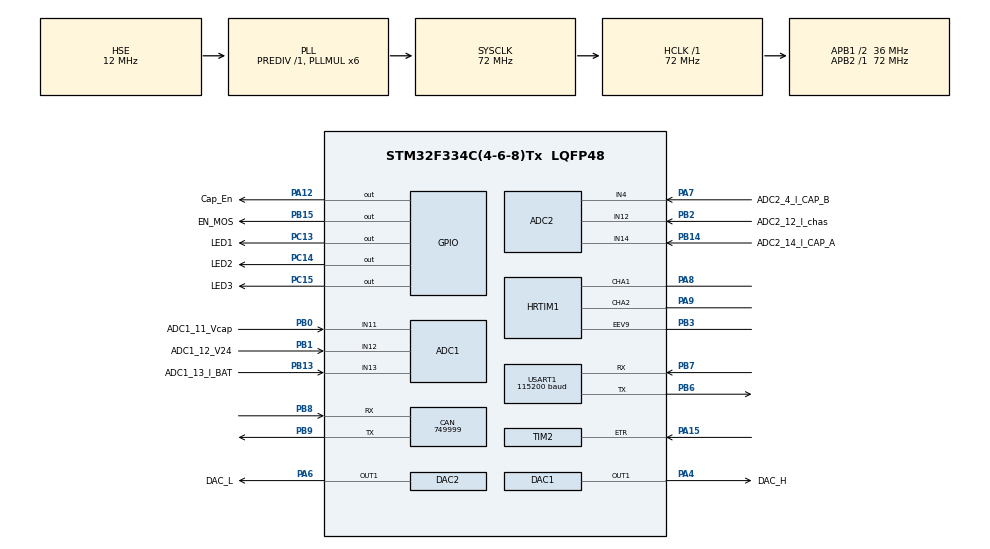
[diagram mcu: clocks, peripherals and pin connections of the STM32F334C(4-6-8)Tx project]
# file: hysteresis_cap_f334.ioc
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ADC1.Channel-1\#ChannelRegularConversion=ADC_CHANNEL_13
ADC1.Channel-2\#ChannelRegularConversion=ADC_CHANNEL_11
ADC1.Channel-3\#ChannelRegularConversion=ADC_CHANNEL_12
ADC1.ContinuousConvMode=ENABLE
ADC1.DMAContinuousRequests=ENABLE
ADC1.NbrOfConversion=3
ADC1.NbrOfConversionFlag=1
ADC1.Offset-1\#ChannelRegularConversion=0
ADC1.Offset-2\#ChannelRegularConversion=0
ADC1.Offset-3\#ChannelRegularConversion=0
ADC1.OffsetNumber-1\#ChannelRegularConversion=ADC_OFFSET_NONE
ADC1.OffsetNumber-2\#ChannelRegularConversion=ADC_OFFSET_NONE
ADC1.OffsetNumber-3\#ChannelRegularConversion=ADC_OFFSET_NONE
ADC1.Rank-1\#ChannelRegularConversion=1
ADC1.Rank-2\#ChannelRegularConversion=2
ADC1.Rank-3\#ChannelRegularConversion=3
ADC1.SamplingTime-1\#ChannelRegularConversion=ADC_SAMPLETIME_19CYCLES_5
ADC1.SamplingTime-2\#ChannelRegularConversion=ADC_SAMPLETIME_19CYCLES_5
ADC1.SamplingTime-3\#ChannelRegularConversion=ADC_SAMPLETIME_19CYCLES_5
ADC1.SubFamily=STM32F334x8
ADC1.master=1
ADC2.Channel-1\#ChannelRegularConversion=ADC_CHANNEL_14
ADC2.Channel-2\#ChannelRegularConversion=ADC_CHANNEL_12
ADC2.Channel-3\#ChannelRegularConversion=ADC_CHANNEL_4
ADC2.ContinuousConvMode=ENABLE
ADC2.DMAContinuousRequests=ENABLE
ADC2.NbrOfConversion=3
ADC2.NbrOfConversionFlag=1
ADC2.Offset-1\#ChannelRegularConversion=0
ADC2.Offset-2\#ChannelRegularConversion=0
ADC2.Offset-3\#ChannelRegularConversion=0
ADC2.OffsetNumber-1\#ChannelRegularConversion=ADC_OFFSET_NONE
ADC2.OffsetNumber-2\#ChannelRegularConversion=ADC_OFFSET_NONE
ADC2.OffsetNumber-3\#ChannelRegularConversion=ADC_OFFSET_NONE
ADC2.Rank-1\#ChannelRegularConversion=1
ADC2.Rank-2\#ChannelRegularConversion=2
ADC2.Rank-3\#ChannelRegularConversion=3
ADC2.SamplingTime-1\#ChannelRegularConversion=ADC_SAMPLETIME_19CYCLES_5
ADC2.SamplingTime-2\#ChannelRegularConversion=ADC_SAMPLETIME_19CYCLES_5
ADC2.SamplingTime-3\#ChannelRegularConversion=ADC_SAMPLETIME_19CYCLES_5
ADC2.SequencerNbRanks=1
CAN.CalculateBaudRate=749999
CAN.CalculateTimeBit=1333
CAN.CalculateTimeQuantum=444.44444444444446
DAC1.DAC_Trigger=DAC_TRIGGER_T15_TRGO
DAC2.DAC_Trigger=DAC_TRIGGER_T15_TRGO
Dma.ADC1.2.Direction=DMA_PERIPH_TO_MEMORY
Dma.ADC1.2.Instance=DMA1_Channel1
Dma.ADC1.2.MemDataAlignment=DMA_MDATAALIGN_HALFWORD
Dma.ADC1.2.MemInc=DMA_MINC_ENABLE
Dma.ADC1.2.Mode=DMA_CIRCULAR
Dma.ADC1.2.PeriphDataAlignment=DMA_PDATAALIGN_HALFWORD
Dma.ADC1.2.PeriphInc=DMA_PINC_DISABLE
Dma.ADC1.2.Priority=DMA_PRIORITY_LOW
Dma.ADC2.3.Direction=DMA_PERIPH_TO_MEMORY
Dma.ADC2.3.Instance=DMA1_Channel2
Dma.ADC2.3.MemDataAlignment=DMA_MDATAALIGN_HALFWORD
Dma.ADC2.3.MemInc=DMA_MINC_ENABLE
Dma.ADC2.3.Mode=DMA_CIRCULAR
Dma.ADC2.3.PeriphDataAlignment=DMA_PDATAALIGN_HALFWORD
Dma.ADC2.3.PeriphInc=DMA_PINC_DISABLE
Dma.ADC2.3.Priority=DMA_PRIORITY_LOW
Dma.Request0=USART1_RX
Dma.Request1=USART1_TX
Dma.Request2=ADC1
Dma.Request3=ADC2
Dma.USART1_RX.0.Direction=DMA_PERIPH_TO_MEMORY
Dma.USART1_RX.0.Instance=DMA1_Channel5
Dma.USART1_RX.0.MemDataAlignment=DMA_MDATAALIGN_BYTE
Dma.USART1_RX.0.MemInc=DMA_MINC_ENABLE
Dma.USART1_RX.0.Mode=DMA_CIRCULAR
Dma.USART1_RX.0.PeriphDataAlignment=DMA_PDATAALIGN_BYTE
Dma.USART1_RX.0.PeriphInc=DMA_PINC_DISABLE
Dma.USART1_RX.0.Priority=DMA_PRIORITY_LOW
Dma.USART1_TX.1.Direction=DMA_MEMORY_TO_PERIPH
Dma.USART1_TX.1.Instance=DMA1_Channel4
Dma.USART1_TX.1.MemDataAlignment=DMA_MDATAALIGN_BYTE
Dma.USART1_TX.1.MemInc=DMA_MINC_ENABLE
Dma.USART1_TX.1.Mode=DMA_NORMAL
Dma.USART1_TX.1.PeriphDataAlignment=DMA_PDATAALIGN_BYTE
Dma.USART1_TX.1.PeriphInc=DMA_PINC_DISABLE
Dma.USART1_TX.1.Priority=DMA_PRIORITY_LOW
HRTIM1.CalibrationRate_nonIT=HRTIM_CALIBRATIONRATE_14
HRTIM1.CompareUnit1-Output_TA1TA2=HRTIM_COMPAREUNIT_1
HRTIM1.CompareUnit2-Output_TA1TA2=HRTIM_COMPAREUNIT_2
HRTIM1.CompareUnit3-Output_TA1TA2=HRTIM_COMPAREUNIT_3
HRTIM1.CompareValue1-Output_TA1TA2=1600
HRTIM1.CompareValue2-Output_TA1TA2=65043
HRTIM1.CompareValue3-Output_TA1TA2=1500
HRTIM1.Enable=HRTIM_BURSTMODECTL_DISABLED
HRTIM1.EnableCalibration=DLLSimpleCalibration
HRTIM1.NumberInterruptRequests-Output_TA1TA2=0
HRTIM1.NumberResetSource1-Output_TA1TA2=2
HRTIM1.NumberResetSource2_TA=1
HRTIM1.NumberResetTrigger-Output_TA1TA2=1
HRTIM1.NumberSetSource1-Output_TA1TA2=1
HRTIM1.NumberSetSource2_TA=1
HRTIM1.NumberUpdateTrigger-Output_TA1TA2=0
HRTIM1.Periode_TA=65503
HRTIM1.Polarity_EEV9=HRTIM_EVENTPOLARITY_HIGH
HRTIM1.PreloadEnable-Output_TA1TA2=HRTIM_PRELOAD_DISABLED
HRTIM1.PrescalerRatio_TA=HRTIM_PRESCALERRATIO_MUL32
HRTIM1.RepetitionUpdate-Output_TA1TA2=HRTIM_UPDATEONREPETITION_DISABLED
HRTIM1.ResetOutput1_Source1-Output_TA1TA2=HRTIM_OUTPUTRESET_NONE
HRTIM1.ResetOutput1_Source2-Output_TA1TA2=HRTIM_OUTPUTRESET_TIMPER
HRTIM1.ResetOutput2_Source1-Output_TA1TA2=HRTIM_OUTPUTRESET_TIMCMP3
HRTIM1.ResetTrigger1-Output_TA1TA2=HRTIM_TIMRESETTRIGGER_EEV_9
HRTIM1.Sensitivity_EEV9=HRTIM_EVENTSENSITIVITY_FALLINGEDGE
HRTIM1.SetOutput1_Source1-Output_TA1TA2=HRTIM_OUTPUTSET_TIMCMP1
HRTIM1.SetOutput2_Source1-Output_TA1TA2=HRTIM_OUTPUTSET_TIMCMP2
HRTIM1.SyncOptions=HRTIM_SYNCOPTION_NONE
Mcu.Family=STM32F3
Mcu.Name=STM32F334C(4-6-8)Tx
Mcu.Package=LQFP48
NVIC.DMA1_Channel4_IRQn=true\:0\:0\:false\:false\:true\:true\:true\:true
NVIC.DMA1_Channel5_IRQn=true\:0\:0\:false\:false\:true\:true\:true\:true
NVIC.PriorityGroup=NVIC_PRIORITYGROUP_4
NVIC.TIM1_BRK_TIM15_IRQn=true\:0\:0\:false\:false\:false\:true\:false\:true
NVIC.USART1_IRQn=true\:0\:0\:false\:false\:true\:true\:true\:true
PA12.GPIO_Label=Cap_En
PA12.Signal=GPIO_Output
PA13.Mode=Serial_Wire
PA13.Signal=SYS_JTMS-SWDIO
PA14.Mode=Serial_Wire
PA14.Signal=SYS_JTCK-SWCLK
PA15.Signal=S_TIM2_CH1_ETR
PA4.GPIO_Label=DAC_H
PA4.Signal=COMP_DAC11_group
PA6.GPIO_Label=DAC_L
PA6.Signal=COMP_DAC21_group
PA7.GPIO_Label=ADC2_4_I_CAP_B
PA7.Mode=IN4-Single-Ended
PA7.Signal=ADC2_IN4
PA8.Mode=Output_TA1TA2
PA8.Signal=HRTIM1_CHA1
PA9.Mode=Output_TA1TA2
PA9.Signal=HRTIM1_CHA2
PB0.GPIO_Label=ADC1_11_Vcap
PB0.Mode=IN11-Single-Ended
PB0.Signal=ADC1_IN11
PB1.GPIO_Label=ADC1_12_V24
PB1.Mode=IN12-Single-Ended
PB1.Signal=ADC1_IN12
PB13.GPIO_Label=ADC1_13_I_BAT
PB13.Mode=IN13-Single-Ended
PB13.Signal=ADC1_IN13
PB14.GPIO_Label=ADC2_14_I_CAP_A
PB14.Mode=IN14-Single-Ended
PB14.Signal=ADC2_IN14
PB15.GPIO_Label=EN_MOS
PB15.Signal=GPIO_Output
PB2.GPIO_Label=ADC2_12_I_chas
PB2.Mode=IN12-Single-Ended
PB2.Signal=ADC2_IN12
PB3.Mode=External_Evt_enable9
PB3.Signal=HRTIM1_EEV9
PB6.Mode=Asynchronous
PB6.Signal=USART1_TX
PB7.Mode=Asynchronous
PB7.Signal=USART1_RX
PB8.Mode=CAN_Activate
PB8.Signal=CAN_RX
PB9.Mode=CAN_Activate
PB9.Signal=CAN_TX
PC13.GPIO_Label=LED1
PC13.Signal=GPIO_Output
PC14\ /\ OSC32_IN.GPIO_Label=LED2
PC14\ /\ OSC32_IN.Signal=GPIO_Output
PC15\ /\ OSC32_OUT.GPIO_Label=LED3
PC15\ /\ OSC32_OUT.Signal=GPIO_Output
PF0\ /\ OSC_IN.Mode=HSE-External-Oscillator
PF0\ /\ OSC_IN.Signal=RCC_OSC_IN
PF1\ /\ OSC_OUT.Mode=HSE-External-Oscillator
PF1\ /\ OSC_OUT.Signal=RCC_OSC_OUT
ProjectManager.HeapSize=0x200
ProjectManager.StackSize=0x400
ProjectManager.TargetToolchain=MDK-ARM V5.32
RCC.AHBFreq_Value=72000000
RCC.APB1CLKDivider=RCC_HCLK_DIV2
RCC.APB1Freq_Value=36000000
RCC.APB1TimFreq_Value=72000000
RCC.APB2Freq_Value=72000000
RCC.APB2TimFreq_Value=72000000
RCC.CortexFreq_Value=72000000
RCC.HCLKFreq_Value=72000000
RCC.HRTIMSelection=RCC_HRTIM1CLK_PLLCLK
RCC.HSE_VALUE=12000000
RCC.HSI_VALUE=8000000
RCC.LSE_VALUE=32768
RCC.PLLMUL=RCC_PLL_MUL6
RCC.PLLSourceVirtual=RCC_PLLSOURCE_HSE
RCC.SYSCLKFreq_VALUE=72000000
RCC.SYSCLKSourceVirtual=RCC_SYSCLKSOURCE_PLLCLK
SH.COMP_DAC11_group.0=DAC1_OUT1,DAC_OUT1
SH.COMP_DAC21_group.0=DAC2_OUT1,Switch_Enable_OUT1
SH.S_TIM2_CH1_ETR.0=TIM2_ETR,ClockSourceETR_Mode2
TIM15.AutoReloadPreload=TIM_AUTORELOAD_PRELOAD_ENABLE
TIM15.Period=9
TIM15.Prescaler=71
TIM15.TIM_MasterOutputTrigger=TIM_TRGO_UPDATE
USART1.BaudRate=115200
USART1.OverSampling=UART_OVERSAMPLING_16
USART1.VirtualMode-Asynchronous=VM_ASYNC
VP_TIM15_VS_ClockSourceINT.Mode=Internal
board=custom

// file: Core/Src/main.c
/* USER CODE BEGIN Header */
/**
  ******************************************************************************
  * @file           : main.c
  * @brief          : Main program body
  ******************************************************************************
  * @attention
  *
  * Copyright (c) 2026 STMicroelectronics.
  * All rights reserved.
  *
  * This software is licensed under terms that can be found in the LICENSE file
  * in the root directory of this software component.
  * If no LICENSE file comes with this software, it is provided AS-IS.
  *
  ******************************************************************************
  */
/* USER CODE END Header */
#include "main.h"
#include "adc.h"
#include "can.h"
#include "dac.h"
#include "dma.h"
#include "hrtim.h"
#include "tim.h"
#include "usart.h"
#include "gpio.h"

/* USER CODE BEGIN Includes */
#include "scheduler.h"
/* USER CODE END Includes */

void SystemClock_Config(void);

int main(void)
{

  /* MCU Configuration--------------------------------------------------------*/

  /* Reset of all peripherals, Initializes the Flash interface and the Systick. */
  HAL_Init();

  /* Configure the system clock */
  SystemClock_Config();

  /* Initialize all configured peripherals */
  MX_GPIO_Init();
  MX_DMA_Init();
  MX_CAN_Init();
  MX_DAC1_Init();
  MX_DAC2_Init();
  MX_HRTIM1_Init();
  MX_USART1_UART_Init();
  MX_TIM2_Init();
  MX_ADC1_Init();
  MX_ADC2_Init();
  MX_TIM15_Init();
  /* USER CODE BEGIN 2 */
  Scheduler_ALL_Init_Task();
  /* USER CODE END 2 */

  /* Infinite loop */
  /* USER CODE BEGIN WHILE */
  while (1)
  {
    Scheduler_run();
    /* USER CODE END WHILE */

  }
}

void SystemClock_Config(void)
{
  RCC_OscInitTypeDef RCC_OscInitStruct = {0};
  RCC_ClkInitTypeDef RCC_ClkInitStruct = {0};
  RCC_PeriphCLKInitTypeDef PeriphClkInit = {0};

  /** Initializes the RCC Oscillators according to the specified parameters
  * in the RCC_OscInitTypeDef structure.
  */
  RCC_OscInitStruct.OscillatorType = RCC_OSCILLATORTYPE_HSE;
  RCC_OscInitStruct.HSEState = RCC_HSE_ON;
  RCC_OscInitStruct.HSEPredivValue = RCC_HSE_PREDIV_DIV1;
  RCC_OscInitStruct.HSIState = RCC_HSI_ON;
  RCC_OscInitStruct.PLL.PLLState = RCC_PLL_ON;
  RCC_OscInitStruct.PLL.PLLSource = RCC_PLLSOURCE_HSE;
  RCC_OscInitStruct.PLL.PLLMUL = RCC_PLL_MUL6;
  if (HAL_RCC_OscConfig(&RCC_OscInitStruct) != HAL_OK)
  {
    Error_Handler();
  }

  /** Initializes the CPU, AHB and APB buses clocks
  */
  RCC_ClkInitStruct.ClockType = RCC_CLOCKTYPE_HCLK|RCC_CLOCKTYPE_SYSCLK
                              |RCC_CLOCKTYPE_PCLK1|RCC_CLOCKTYPE_PCLK2;
  RCC_ClkInitStruct.SYSCLKSource = RCC_SYSCLKSOURCE_PLLCLK;
  RCC_ClkInitStruct.AHBCLKDivider = RCC_SYSCLK_DIV1;
  RCC_ClkInitStruct.APB1CLKDivider = RCC_HCLK_DIV2;
  RCC_ClkInitStruct.APB2CLKDivider = RCC_HCLK_DIV1;

  if (HAL_RCC_ClockConfig(&RCC_ClkInitStruct, FLASH_LATENCY_2) != HAL_OK)
  {
    Error_Handler();
  }
  PeriphClkInit.PeriphClockSelection = RCC_PERIPHCLK_HRTIM1|RCC_PERIPHCLK_USART1
                              |RCC_PERIPHCLK_ADC12;
  PeriphClkInit.Usart1ClockSelection = RCC_USART1CLKSOURCE_PCLK1;
  PeriphClkInit.Adc12ClockSelection = RCC_ADC12PLLCLK_DIV1;
  PeriphClkInit.Hrtim1ClockSelection = RCC_HRTIM1CLK_PLLCLK;
  if (HAL_RCCEx_PeriphCLKConfig(&PeriphClkInit) != HAL_OK)
  {
    Error_Handler();
  }
}

void Error_Handler(void)
{
  __disable_irq();
  while (1)
  {
  }
}
